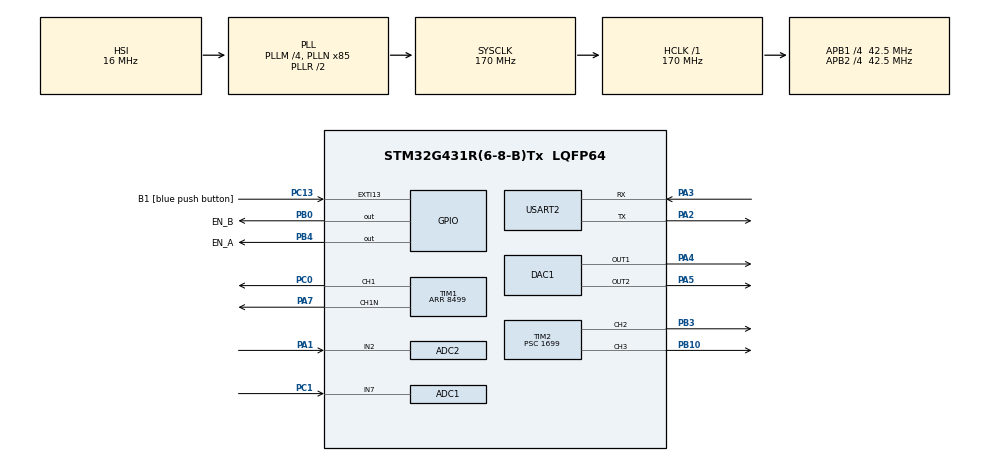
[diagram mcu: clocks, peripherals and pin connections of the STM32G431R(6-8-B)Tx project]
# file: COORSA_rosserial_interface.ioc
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ADC1.Channel-0\#ChannelRegularConversion=ADC_CHANNEL_7
ADC1.Mode=ADC_DUALMODE_REGSIMULT
ADC1.NbrOfConversionFlag=1
ADC1.OffsetNumber-0\#ChannelRegularConversion=ADC_OFFSET_NONE
ADC1.Overrun=ADC_OVR_DATA_OVERWRITTEN
ADC1.Rank-0\#ChannelRegularConversion=1
ADC1.Resolution=ADC_RESOLUTION_10B
ADC1.SamplingTime-0\#ChannelRegularConversion=ADC_SAMPLETIME_2CYCLES_5
ADC1.master=1
ADC2.Channel-0\#ChannelRegularConversion=ADC_CHANNEL_2
ADC2.Mode=ADC_DUALMODE_REGSIMULT
ADC2.NbrOfConversionFlag=1
ADC2.OffsetNumber-0\#ChannelRegularConversion=ADC_OFFSET_NONE
ADC2.Overrun=ADC_OVR_DATA_OVERWRITTEN
ADC2.Rank-0\#ChannelRegularConversion=1
ADC2.Resolution=ADC_RESOLUTION_10B
ADC2.SamplingTime-0\#ChannelRegularConversion=ADC_SAMPLETIME_2CYCLES_5
DAC1.DAC_Channel-DAC_OUT2=DAC_CHANNEL_2
Dma.Request0=USART2_RX
Dma.Request1=USART2_TX
Dma.USART2_RX.0.Direction=DMA_PERIPH_TO_MEMORY
Dma.USART2_RX.0.EventEnable=DISABLE
Dma.USART2_RX.0.Instance=DMA1_Channel1
Dma.USART2_RX.0.MemDataAlignment=DMA_MDATAALIGN_BYTE
Dma.USART2_RX.0.MemInc=DMA_MINC_ENABLE
Dma.USART2_RX.0.Mode=DMA_CIRCULAR
Dma.USART2_RX.0.PeriphDataAlignment=DMA_PDATAALIGN_BYTE
Dma.USART2_RX.0.PeriphInc=DMA_PINC_DISABLE
Dma.USART2_RX.0.Polarity=HAL_DMAMUX_REQ_GEN_RISING
Dma.USART2_RX.0.Priority=DMA_PRIORITY_HIGH
Dma.USART2_RX.0.RequestNumber=1
Dma.USART2_RX.0.SignalID=NONE
Dma.USART2_RX.0.SyncEnable=DISABLE
Dma.USART2_RX.0.SyncPolarity=HAL_DMAMUX_SYNC_NO_EVENT
Dma.USART2_RX.0.SyncRequestNumber=1
Dma.USART2_RX.0.SyncSignalID=NONE
Dma.USART2_TX.1.Direction=DMA_MEMORY_TO_PERIPH
Dma.USART2_TX.1.EventEnable=DISABLE
Dma.USART2_TX.1.Instance=DMA1_Channel2
Dma.USART2_TX.1.MemDataAlignment=DMA_MDATAALIGN_BYTE
Dma.USART2_TX.1.MemInc=DMA_MINC_ENABLE
Dma.USART2_TX.1.Mode=DMA_NORMAL
Dma.USART2_TX.1.PeriphDataAlignment=DMA_PDATAALIGN_BYTE
Dma.USART2_TX.1.PeriphInc=DMA_PINC_DISABLE
Dma.USART2_TX.1.Polarity=HAL_DMAMUX_REQ_GEN_RISING
Dma.USART2_TX.1.Priority=DMA_PRIORITY_HIGH
Dma.USART2_TX.1.RequestNumber=1
Dma.USART2_TX.1.SignalID=NONE
Dma.USART2_TX.1.SyncEnable=DISABLE
Dma.USART2_TX.1.SyncPolarity=HAL_DMAMUX_SYNC_NO_EVENT
Dma.USART2_TX.1.SyncRequestNumber=1
Dma.USART2_TX.1.SyncSignalID=NONE
Mcu.Family=STM32G4
Mcu.Name=STM32G431R(6-8-B)Tx
Mcu.Package=LQFP64
NVIC.DMA1_Channel1_IRQn=true\:0\:0\:false\:false\:true\:false\:true
NVIC.DMA1_Channel2_IRQn=true\:0\:0\:false\:false\:true\:false\:true
NVIC.PriorityGroup=NVIC_PRIORITYGROUP_4
NVIC.TIM1_UP_TIM16_IRQn=true\:0\:0\:false\:false\:true\:true\:true
NVIC.USART2_IRQn=true\:0\:0\:false\:false\:true\:true\:true
PA1.Mode=IN2-Single-Ended
PA1.Signal=ADC2_IN2
PA2.Mode=Asynchronous
PA2.Signal=USART2_TX
PA3.Mode=Asynchronous
PA3.Signal=USART2_RX
PA4.Signal=COMP_DAC11_group
PA5.Signal=COMP_DAC12_group
PA7.Mode=PWM Generation1 CH1 CH1N
PA7.Signal=TIM1_CH1N
PB0.GPIO_Label=EN_B
PB0.Signal=GPIO_Output
PB10.Signal=S_TIM2_CH3
PB3.Signal=S_TIM2_CH2
PB4.GPIO_Label=EN_A
PB4.Signal=GPIO_Output
PC0.Signal=S_TIM1_CH1
PC1.Mode=IN7-Single-Ended
PC1.Signal=ADC1_IN7
PC13.GPIO_Label=B1 [blue push button]
PC13.Signal=GPXTI13
ProjectManager.HeapSize=0x200
ProjectManager.StackSize=0x400
ProjectManager.TargetToolchain=STM32CubeIDE
RCC.ADC12Freq_Value=170000000
RCC.AHBFreq_Value=170000000
RCC.APB1CLKDivider=RCC_HCLK_DIV4
RCC.APB1Freq_Value=42500000
RCC.APB1TimFreq_Value=85000000
RCC.APB2CLKDivider=RCC_HCLK_DIV4
RCC.APB2Freq_Value=42500000
RCC.APB2TimFreq_Value=85000000
RCC.CortexFreq_Value=170000000
RCC.EXTERNAL_CLOCK_VALUE=12288000
RCC.HCLKFreq_Value=170000000
RCC.HSE_VALUE=24000000
RCC.HSI48_VALUE=48000000
RCC.HSI_VALUE=16000000
RCC.LSE_VALUE=32768
RCC.PLLM=RCC_PLLM_DIV4
RCC.PLLN=85
RCC.RTCClockSelection=RCC_RTCCLKSOURCE_LSE
RCC.SYSCLKFreq_VALUE=170000000
RCC.SYSCLKSource=RCC_SYSCLKSOURCE_PLLCLK
RCC.USART2CLockSelection=RCC_USART2CLKSOURCE_SYSCLK
RCC.USBFreq_Value=170000000
RCC.VCOOutputFreq_Value=340000000
SH.COMP_DAC11_group.0=DAC1_OUT1,DAC_OUT1
SH.COMP_DAC12_group.0=DAC1_OUT2,DAC_OUT2
SH.S_TIM1_CH1.0=TIM1_CH1,PWM Generation1 CH1 CH1N
SH.S_TIM2_CH2.0=TIM2_CH2,PWM Generation2 CH2
SH.S_TIM2_CH3.0=TIM2_CH3,PWM Generation3 CH3
TIM1.Channel-PWM\ Generation1\ CH1\ CH1N=TIM_CHANNEL_1
TIM1.DeadTime=50
TIM1.PeriodNoDither=8499
TIM2.Channel-PWM\ Generation2\ CH2=TIM_CHANNEL_2
TIM2.Channel-PWM\ Generation3\ CH3=TIM_CHANNEL_3
TIM2.PeriodNoDither=999
TIM2.Prescaler=1699
USART2.VirtualMode-Asynchronous=VM_ASYNC
VP_SYS_VS_DBSignals.Mode=DisableDeadBatterySignals
board=NUCLEO-G431RB

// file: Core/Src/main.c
/* USER CODE BEGIN Header */
/**
  ******************************************************************************
  * @file           : main.c
  * @brief          : Main program body
  ******************************************************************************
  * @attention
  *
  * <h2><center>&copy; Copyright (c) 2020 STMicroelectronics.
  * All rights reserved.</center></h2>
  *
  * This software component is licensed by ST under BSD 3-Clause license,
  * the "License"; You may not use this file except in compliance with the
  * License. You may obtain a copy of the License at:
  *                        opensource.org/licenses/BSD-3-Clause
  *
  ******************************************************************************
  */
/* USER CODE END Header */
#include "main.h"

/* USER CODE BEGIN Includes */
#include "mainpp.h"
#include "stm32g4xx_it.h"
/* USER CODE END Includes */

int pwm_flag = 0;

ADC_HandleTypeDef hadc1;
ADC_HandleTypeDef hadc2;

DAC_HandleTypeDef hdac1;

TIM_HandleTypeDef htim1;
TIM_HandleTypeDef htim2;

UART_HandleTypeDef huart2;
DMA_HandleTypeDef hdma_usart2_rx;
DMA_HandleTypeDef hdma_usart2_tx;

void SystemClock_Config(void);
static void MX_GPIO_Init(void);
static void MX_DMA_Init(void);
static void MX_USART2_UART_Init(void);
static void MX_ADC1_Init(void);
static void MX_ADC2_Init(void);
static void MX_TIM1_Init(void);
static void MX_TIM2_Init(void);
static void MX_DAC1_Init(void);

int main(void)
{

  /* MCU Configuration--------------------------------------------------------*/

  /* Reset of all peripherals, Initializes the Flash interface and the Systick. */
  HAL_Init();

  /* Configure the system clock */
  SystemClock_Config();

  /* USER CODE BEGIN SysInit */
  /*
  __HAL_RCC_GPIOC_CLK_ENABLE();
  GPIO_InitTypeDef   GPIO_InitStructure;
  GPIO_InitStructure.Mode=GPIO_MODE_IT_FALLING;
  GPIO_InitStructure.Pull=GPIO_NOPULL;
  GPIO_InitStructure.Pin=GPIO_PIN_13;
  HAL_GPIO_Init(GPIOC,&GPIO_InitStructure);
  HAL_NVIC_SetPriority(EXTI15_10_IRQn,2,0);
  HAL_NVIC_EnableIRQ(EXTI15_10_IRQn);
  */

  /* USER CODE END SysInit */

  /* Initialize all configured peripherals */
  MX_GPIO_Init();
  MX_DMA_Init();
  MX_USART2_UART_Init();
  MX_ADC1_Init();
  MX_ADC2_Init();
  MX_TIM1_Init();
  MX_TIM2_Init();
  MX_DAC1_Init();
  /* USER CODE BEGIN 2 */
  setup();

  HAL_TIM_PWM_Init(&htim1);	//Inizializzazione PWM H-Bridge Attuatore Lineare
  HAL_TIM_PWM_Init(&htim2); //Inizializzazione PWM Servo Motors

  HAL_TIM_PWM_Start(&htim1, TIM_CHANNEL_1);			//Start PWM + PWM_N H-Bridge Attuatore Lineare
  HAL_TIMEx_PWMN_Start(&htim1, TIM_CHANNEL_1);

  HAL_TIM_PWM_Start(&htim2, TIM_CHANNEL_2);			//Start PWM Servo Motors
  HAL_TIM_PWM_Start(&htim2, TIM_CHANNEL_3);

  HAL_ADC_Start(&hadc1);	//Start ADC
  HAL_ADC_Start(&hadc2);

  HAL_DAC_Start(&hdac1, DAC_CHANNEL_1);						//Start DAC
  HAL_DAC_Start(&hdac1, DAC_CHANNEL_2);

  InitSystem();		//Inizializzazione Variabili di controllo e abilitazione modulazione PWM H-Bridge Attuatore Lineare

  HAL_TIM_Base_Start_IT(&htim1);	//Start Update Interrupt TIM1
  /* USER CODE END 2 */

  /* Infinite loop */
  /* USER CODE BEGIN WHILE */
  while (1)
  {
	loop();
    /* USER CODE END WHILE */
    if(HAL_GPIO_ReadPin (GPIOA, GPIO_PIN_15))
    {
    	if(pwm_flag == 0){
			pwm_flag = 1;
			HAL_TIM_PWM_Start(&htim1, TIM_CHANNEL_1);			//Stop PWM + PWM_N H-Bridge Attuatore Lineare
			HAL_TIMEx_PWMN_Start(&htim1, TIM_CHANNEL_1);
    	}
    }
    else
    {
    	if(pwm_flag == 1){
    		pwm_flag = 0;
    		HAL_TIM_PWM_Stop(&htim1, TIM_CHANNEL_1);			//Start PWM + PWM_N H-Bridge Attuatore Lineare
    		HAL_TIMEx_PWMN_Stop(&htim1, TIM_CHANNEL_1);
    	}
    }
  }
}

void SystemClock_Config(void)
{
  RCC_OscInitTypeDef RCC_OscInitStruct = {0};
  RCC_ClkInitTypeDef RCC_ClkInitStruct = {0};
  RCC_PeriphCLKInitTypeDef PeriphClkInit = {0};

  /** Configure the main internal regulator output voltage
  */
  HAL_PWREx_ControlVoltageScaling(PWR_REGULATOR_VOLTAGE_SCALE1_BOOST);
  /** Initializes the RCC Oscillators according to the specified parameters
  * in the RCC_OscInitTypeDef structure.
  */
  RCC_OscInitStruct.OscillatorType = RCC_OSCILLATORTYPE_HSI;
  RCC_OscInitStruct.HSIState = RCC_HSI_ON;
  RCC_OscInitStruct.HSICalibrationValue = RCC_HSICALIBRATION_DEFAULT;
  RCC_OscInitStruct.PLL.PLLState = RCC_PLL_ON;
  RCC_OscInitStruct.PLL.PLLSource = RCC_PLLSOURCE_HSI;
  RCC_OscInitStruct.PLL.PLLM = RCC_PLLM_DIV4;
  RCC_OscInitStruct.PLL.PLLN = 85;
  RCC_OscInitStruct.PLL.PLLP = RCC_PLLP_DIV2;
  RCC_OscInitStruct.PLL.PLLQ = RCC_PLLQ_DIV2;
  RCC_OscInitStruct.PLL.PLLR = RCC_PLLR_DIV2;
  if (HAL_RCC_OscConfig(&RCC_OscInitStruct) != HAL_OK)
  {
    Error_Handler();
  }
  /** Initializes the CPU, AHB and APB buses clocks
  */
  RCC_ClkInitStruct.ClockType = RCC_CLOCKTYPE_HCLK|RCC_CLOCKTYPE_SYSCLK
                              |RCC_CLOCKTYPE_PCLK1|RCC_CLOCKTYPE_PCLK2;
  RCC_ClkInitStruct.SYSCLKSource = RCC_SYSCLKSOURCE_PLLCLK;
  RCC_ClkInitStruct.AHBCLKDivider = RCC_SYSCLK_DIV1;
  RCC_ClkInitStruct.APB1CLKDivider = RCC_HCLK_DIV4;
  RCC_ClkInitStruct.APB2CLKDivider = RCC_HCLK_DIV4;

  if (HAL_RCC_ClockConfig(&RCC_ClkInitStruct, FLASH_LATENCY_4) != HAL_OK)
  {
    Error_Handler();
  }
  /** Initializes the peripherals clocks
  */
  PeriphClkInit.PeriphClockSelection = RCC_PERIPHCLK_USART2|RCC_PERIPHCLK_ADC12;
  PeriphClkInit.Usart2ClockSelection = RCC_USART2CLKSOURCE_SYSCLK;
  PeriphClkInit.Adc12ClockSelection = RCC_ADC12CLKSOURCE_SYSCLK;
  if (HAL_RCCEx_PeriphCLKConfig(&PeriphClkInit) != HAL_OK)
  {
    Error_Handler();
  }
}

static void MX_ADC1_Init(void)
{

  ADC_MultiModeTypeDef multimode = {0};
  ADC_ChannelConfTypeDef sConfig = {0};

  /** Common config
  */
  hadc1.Instance = ADC1;
  hadc1.Init.ClockPrescaler = ADC_CLOCK_SYNC_PCLK_DIV4;
  hadc1.Init.Resolution = ADC_RESOLUTION_10B;
  hadc1.Init.DataAlign = ADC_DATAALIGN_RIGHT;
  hadc1.Init.GainCompensation = 0;
  hadc1.Init.ScanConvMode = ADC_SCAN_DISABLE;
  hadc1.Init.EOCSelection = ADC_EOC_SINGLE_CONV;
  hadc1.Init.LowPowerAutoWait = DISABLE;
  hadc1.Init.ContinuousConvMode = DISABLE;
  hadc1.Init.NbrOfConversion = 1;
  hadc1.Init.DiscontinuousConvMode = DISABLE;
  hadc1.Init.ExternalTrigConv = ADC_SOFTWARE_START;
  hadc1.Init.ExternalTrigConvEdge = ADC_EXTERNALTRIGCONVEDGE_NONE;
  hadc1.Init.DMAContinuousRequests = DISABLE;
  hadc1.Init.Overrun = ADC_OVR_DATA_OVERWRITTEN;
  hadc1.Init.OversamplingMode = DISABLE;
  if (HAL_ADC_Init(&hadc1) != HAL_OK)
  {
    Error_Handler();
  }
  /** Configure the ADC multi-mode
  */
  multimode.Mode = ADC_DUALMODE_REGSIMULT;
  multimode.DMAAccessMode = ADC_DMAACCESSMODE_DISABLED;
  multimode.TwoSamplingDelay = ADC_TWOSAMPLINGDELAY_1CYCLE;
  if (HAL_ADCEx_MultiModeConfigChannel(&hadc1, &multimode) != HAL_OK)
  {
    Error_Handler();
  }
  /** Configure Regular Channel
  */
  sConfig.Channel = ADC_CHANNEL_7;
  sConfig.Rank = ADC_REGULAR_RANK_1;
  sConfig.SamplingTime = ADC_SAMPLETIME_2CYCLES_5;
  sConfig.SingleDiff = ADC_SINGLE_ENDED;
  sConfig.OffsetNumber = ADC_OFFSET_NONE;
  sConfig.Offset = 0;
  if (HAL_ADC_ConfigChannel(&hadc1, &sConfig) != HAL_OK)
  {
    Error_Handler();
  }

}

static void MX_ADC2_Init(void)
{

  ADC_ChannelConfTypeDef sConfig = {0};

  /** Common config
  */
  hadc2.Instance = ADC2;
  hadc2.Init.ClockPrescaler = ADC_CLOCK_SYNC_PCLK_DIV4;
  hadc2.Init.Resolution = ADC_RESOLUTION_10B;
  hadc2.Init.DataAlign = ADC_DATAALIGN_RIGHT;
  hadc2.Init.GainCompensation = 0;
  hadc2.Init.ScanConvMode = ADC_SCAN_DISABLE;
  hadc2.Init.EOCSelection = ADC_EOC_SINGLE_CONV;
  hadc2.Init.LowPowerAutoWait = DISABLE;
  hadc2.Init.ContinuousConvMode = DISABLE;
  hadc2.Init.NbrOfConversion = 1;
  hadc2.Init.DiscontinuousConvMode = DISABLE;
  hadc2.Init.DMAContinuousRequests = DISABLE;
  hadc2.Init.Overrun = ADC_OVR_DATA_OVERWRITTEN;
  hadc2.Init.OversamplingMode = DISABLE;
  if (HAL_ADC_Init(&hadc2) != HAL_OK)
  {
    Error_Handler();
  }
  /** Configure Regular Channel
  */
  sConfig.Channel = ADC_CHANNEL_2;
  sConfig.Rank = ADC_REGULAR_RANK_1;
  sConfig.SamplingTime = ADC_SAMPLETIME_2CYCLES_5;
  sConfig.SingleDiff = ADC_SINGLE_ENDED;
  sConfig.OffsetNumber = ADC_OFFSET_NONE;
  sConfig.Offset = 0;
  if (HAL_ADC_ConfigChannel(&hadc2, &sConfig) != HAL_OK)
  {
    Error_Handler();
  }

}

static void MX_DAC1_Init(void)
{

  DAC_ChannelConfTypeDef sConfig = {0};

  /** DAC Initialization
  */
  hdac1.Instance = DAC1;
  if (HAL_DAC_Init(&hdac1) != HAL_OK)
  {
    Error_Handler();
  }
  /** DAC channel OUT1 config
  */
  sConfig.DAC_HighFrequency = DAC_HIGH_FREQUENCY_INTERFACE_MODE_AUTOMATIC;
  sConfig.DAC_DMADoubleDataMode = DISABLE;
  sConfig.DAC_SignedFormat = DISABLE;
  sConfig.DAC_SampleAndHold = DAC_SAMPLEANDHOLD_DISABLE;
  sConfig.DAC_Trigger = DAC_TRIGGER_NONE;
  sConfig.DAC_Trigger2 = DAC_TRIGGER_NONE;
  sConfig.DAC_OutputBuffer = DAC_OUTPUTBUFFER_ENABLE;
  sConfig.DAC_ConnectOnChipPeripheral = DAC_CHIPCONNECT_EXTERNAL;
  sConfig.DAC_UserTrimming = DAC_TRIMMING_FACTORY;
  if (HAL_DAC_ConfigChannel(&hdac1, &sConfig, DAC_CHANNEL_1) != HAL_OK)
  {
    Error_Handler();
  }
  /** DAC channel OUT2 config
  */
  sConfig.DAC_ConnectOnChipPeripheral = DAC_CHIPCONNECT_EXTERNAL;
  if (HAL_DAC_ConfigChannel(&hdac1, &sConfig, DAC_CHANNEL_2) != HAL_OK)
  {
    Error_Handler();
  }

}

static void MX_TIM1_Init(void)
{

  TIM_MasterConfigTypeDef sMasterConfig = {0};
  TIM_OC_InitTypeDef sConfigOC = {0};
  TIM_BreakDeadTimeConfigTypeDef sBreakDeadTimeConfig = {0};

  htim1.Instance = TIM1;
  htim1.Init.Prescaler = 0;
  htim1.Init.CounterMode = TIM_COUNTERMODE_UP;
  htim1.Init.Period = 8499;
  htim1.Init.ClockDivision = TIM_CLOCKDIVISION_DIV1;
  htim1.Init.RepetitionCounter = 0;
  htim1.Init.AutoReloadPreload = TIM_AUTORELOAD_PRELOAD_DISABLE;
  if (HAL_TIM_PWM_Init(&htim1) != HAL_OK)
  {
    Error_Handler();
  }
  sMasterConfig.MasterOutputTrigger = TIM_TRGO_RESET;
  sMasterConfig.MasterOutputTrigger2 = TIM_TRGO2_RESET;
  sMasterConfig.MasterSlaveMode = TIM_MASTERSLAVEMODE_DISABLE;
  if (HAL_TIMEx_MasterConfigSynchronization(&htim1, &sMasterConfig) != HAL_OK)
  {
    Error_Handler();
  }
  sConfigOC.OCMode = TIM_OCMODE_PWM1;
  sConfigOC.Pulse = 0;
  sConfigOC.OCPolarity = TIM_OCPOLARITY_HIGH;
  sConfigOC.OCNPolarity = TIM_OCNPOLARITY_HIGH;
  sConfigOC.OCFastMode = TIM_OCFAST_DISABLE;
  sConfigOC.OCIdleState = TIM_OCIDLESTATE_RESET;
  sConfigOC.OCNIdleState = TIM_OCNIDLESTATE_RESET;
  if (HAL_TIM_PWM_ConfigChannel(&htim1, &sConfigOC, TIM_CHANNEL_1) != HAL_OK)
  {
    Error_Handler();
  }
  sBreakDeadTimeConfig.OffStateRunMode = TIM_OSSR_DISABLE;
  sBreakDeadTimeConfig.OffStateIDLEMode = TIM_OSSI_DISABLE;
  sBreakDeadTimeConfig.LockLevel = TIM_LOCKLEVEL_OFF;
  sBreakDeadTimeConfig.DeadTime = 50;
  sBreakDeadTimeConfig.BreakState = TIM_BREAK_DISABLE;
  sBreakDeadTimeConfig.BreakPolarity = TIM_BREAKPOLARITY_HIGH;
  sBreakDeadTimeConfig.BreakFilter = 0;
  sBreakDeadTimeConfig.BreakAFMode = TIM_BREAK_AFMODE_INPUT;
  sBreakDeadTimeConfig.Break2State = TIM_BREAK2_DISABLE;
  sBreakDeadTimeConfig.Break2Polarity = TIM_BREAK2POLARITY_HIGH;
  sBreakDeadTimeConfig.Break2Filter = 0;
  sBreakDeadTimeConfig.Break2AFMode = TIM_BREAK_AFMODE_INPUT;
  sBreakDeadTimeConfig.AutomaticOutput = TIM_AUTOMATICOUTPUT_DISABLE;
  if (HAL_TIMEx_ConfigBreakDeadTime(&htim1, &sBreakDeadTimeConfig) != HAL_OK)
  {
    Error_Handler();
  }
  HAL_TIM_MspPostInit(&htim1);

}

static void MX_TIM2_Init(void)
{

  TIM_MasterConfigTypeDef sMasterConfig = {0};
  TIM_OC_InitTypeDef sConfigOC = {0};

  htim2.Instance = TIM2;
  htim2.Init.Prescaler = 1699;
  htim2.Init.CounterMode = TIM_COUNTERMODE_UP;
  htim2.Init.Period = 999;
  htim2.Init.ClockDivision = TIM_CLOCKDIVISION_DIV1;
  htim2.Init.AutoReloadPreload = TIM_AUTORELOAD_PRELOAD_DISABLE;
  if (HAL_TIM_PWM_Init(&htim2) != HAL_OK)
  {
    Error_Handler();
  }
  sMasterConfig.MasterOutputTrigger = TIM_TRGO_RESET;
  sMasterConfig.MasterSlaveMode = TIM_MASTERSLAVEMODE_DISABLE;
  if (HAL_TIMEx_MasterConfigSynchronization(&htim2, &sMasterConfig) != HAL_OK)
  {
    Error_Handler();
  }
  sConfigOC.OCMode = TIM_OCMODE_PWM1;
  sConfigOC.Pulse = 0;
  sConfigOC.OCPolarity = TIM_OCPOLARITY_HIGH;
  sConfigOC.OCFastMode = TIM_OCFAST_DISABLE;
  if (HAL_TIM_PWM_ConfigChannel(&htim2, &sConfigOC, TIM_CHANNEL_2) != HAL_OK)
  {
    Error_Handler();
  }
  sConfigOC.Pulse = 0;
  if (HAL_TIM_PWM_ConfigChannel(&htim2, &sConfigOC, TIM_CHANNEL_3) != HAL_OK)
  {
    Error_Handler();
  }
  HAL_TIM_MspPostInit(&htim2);

}

static void MX_USART2_UART_Init(void)
{

  huart2.Instance = USART2;
  huart2.Init.BaudRate = 57600;
  huart2.Init.WordLength = UART_WORDLENGTH_8B;
  huart2.Init.StopBits = UART_STOPBITS_1;
  huart2.Init.Parity = UART_PARITY_NONE;
  huart2.Init.Mode = UART_MODE_TX_RX;
  huart2.Init.HwFlowCtl = UART_HWCONTROL_NONE;
  huart2.Init.OverSampling = UART_OVERSAMPLING_16;
  huart2.Init.OneBitSampling = UART_ONE_BIT_SAMPLE_DISABLE;
  huart2.Init.ClockPrescaler = UART_PRESCALER_DIV1;
  huart2.AdvancedInit.AdvFeatureInit = UART_ADVFEATURE_NO_INIT;
  if (HAL_UART_Init(&huart2) != HAL_OK)
  {
    Error_Handler();
  }
  if (HAL_UARTEx_SetTxFifoThreshold(&huart2, UART_TXFIFO_THRESHOLD_1_8) != HAL_OK)
  {
    Error_Handler();
  }
  if (HAL_UARTEx_SetRxFifoThreshold(&huart2, UART_RXFIFO_THRESHOLD_1_8) != HAL_OK)
  {
    Error_Handler();
  }
  if (HAL_UARTEx_DisableFifoMode(&huart2) != HAL_OK)
  {
    Error_Handler();
  }

}

static void MX_DMA_Init(void)
{

  /* DMA controller clock enable */
  __HAL_RCC_DMAMUX1_CLK_ENABLE();
  __HAL_RCC_DMA1_CLK_ENABLE();

  /* DMA interrupt init */
  /* DMA1_Channel1_IRQn interrupt configuration */
  HAL_NVIC_SetPriority(DMA1_Channel1_IRQn, 0, 0);
  HAL_NVIC_EnableIRQ(DMA1_Channel1_IRQn);
  /* DMA1_Channel2_IRQn interrupt configuration */
  HAL_NVIC_SetPriority(DMA1_Channel2_IRQn, 0, 0);
  HAL_NVIC_EnableIRQ(DMA1_Channel2_IRQn);

}

static void MX_GPIO_Init(void)
{
  GPIO_InitTypeDef GPIO_InitStruct = {0};

  /* GPIO Ports Clock Enable */
  __HAL_RCC_GPIOC_CLK_ENABLE();
  __HAL_RCC_GPIOA_CLK_ENABLE();
  __HAL_RCC_GPIOB_CLK_ENABLE();

  /*Configure GPIO pin Output Level */
  HAL_GPIO_WritePin(GPIOB, EN_B_Pin|EN_A_Pin, GPIO_PIN_RESET);

  /*Configure GPIO pin : B1_Pin */
  GPIO_InitStruct.Pin = B1_Pin;
  GPIO_InitStruct.Mode = GPIO_MODE_IT_RISING;
  GPIO_InitStruct.Pull = GPIO_NOPULL;
  HAL_GPIO_Init(B1_GPIO_Port, &GPIO_InitStruct);

  /*Configure GPIO pins : EN_B_Pin EN_A_Pin */
  GPIO_InitStruct.Pin = EN_B_Pin|EN_A_Pin;
  GPIO_InitStruct.Mode = GPIO_MODE_OUTPUT_PP;
  GPIO_InitStruct.Pull = GPIO_NOPULL;
  GPIO_InitStruct.Speed = GPIO_SPEED_FREQ_LOW;
  HAL_GPIO_Init(GPIOB, &GPIO_InitStruct);

  /*Configure GPIO pin : PA15 */
  GPIO_InitStruct.Pin = GPIO_PIN_15;
  GPIO_InitStruct.Mode = GPIO_MODE_INPUT;
  GPIO_InitStruct.Pull = GPIO_PULLDOWN;
  HAL_GPIO_Init(GPIOA, &GPIO_InitStruct);

}

/* USER CODE BEGIN 4 */
void HAL_GPIO_EXTI_Callback(uint16_t GPIO_Pin)
{
  if (GPIO_Pin == GPIO_PIN_13)
  {
    /* Toggle LED2 */
	  HAL_GPIO_TogglePin(GPIOA,GPIO_PIN_5);
  }
}

/* USER CODE END 4 */

void Error_Handler(void)
{
}

/************************ (C) COPYRIGHT STMicroelectronics *****END OF FILE****/
